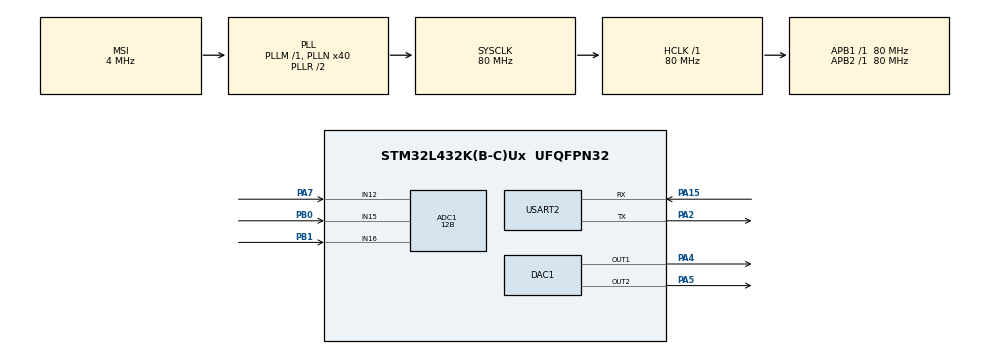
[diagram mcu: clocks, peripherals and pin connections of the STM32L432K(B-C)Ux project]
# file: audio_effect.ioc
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ADC1.Channel-0\#ChannelRegularConversion=ADC_CHANNEL_15
ADC1.Channel-3\#ChannelRegularConversion=ADC_CHANNEL_16
ADC1.Channel-4\#ChannelRegularConversion=ADC_CHANNEL_12
ADC1.ClockPrescaler=ADC_CLOCK_ASYNC_DIV1
ADC1.ContinuousConvMode=DISABLE
ADC1.DMAContinuousRequests=DISABLE
ADC1.DataAlign=ADC_DATAALIGN_RIGHT
ADC1.DiscontinuousConvMode=DISABLE
ADC1.EOCSelection=ADC_EOC_SINGLE_CONV
ADC1.EnableAnalogWatchDog1=false
ADC1.EnableAnalogWatchDog2=false
ADC1.EnableAnalogWatchDog3=false
ADC1.EnableInjectedConversion=DISABLE
ADC1.EnableRegularConversion=ENABLE
ADC1.ExternalTrigConv=ADC_SOFTWARE_START
ADC1.ExternalTrigConvEdge=ADC_EXTERNALTRIGCONVEDGE_NONE
ADC1.LowPowerAutoWait=DISABLE
ADC1.NbrOfConversion=3
ADC1.NbrOfConversionFlag=1
ADC1.OffsetNumber-0\#ChannelRegularConversion=ADC_OFFSET_NONE
ADC1.OffsetNumber-3\#ChannelRegularConversion=ADC_OFFSET_NONE
ADC1.OffsetNumber-4\#ChannelRegularConversion=ADC_OFFSET_NONE
ADC1.Overrun=ADC_OVR_DATA_PRESERVED
ADC1.OversamplingMode=DISABLE
ADC1.Rank-0\#ChannelRegularConversion=1
ADC1.Rank-3\#ChannelRegularConversion=2
ADC1.Rank-4\#ChannelRegularConversion=3
ADC1.Resolution=ADC_RESOLUTION_12B
ADC1.SamplingTime-0\#ChannelRegularConversion=ADC_SAMPLETIME_6CYCLES_5
ADC1.SamplingTime-3\#ChannelRegularConversion=ADC_SAMPLETIME_2CYCLES_5
ADC1.SamplingTime-4\#ChannelRegularConversion=ADC_SAMPLETIME_2CYCLES_5
ADC1.ScanConvMode=ADC_SCAN_ENABLE
ADC1.master=1
DAC1.DAC_Channel-DAC_OUT2=DAC_CHANNEL_2
DAC1.DAC_OutputBuffer-DAC_OUT1=DAC_OUTPUTBUFFER_DISABLE
DAC1.DAC_OutputBuffer-DAC_OUT2=DAC_OUTPUTBUFFER_DISABLE
DAC1.DAC_SampleAndHold-DAC_OUT1=DAC_SAMPLEANDHOLD_DISABLE
DAC1.DAC_Trigger-DAC_OUT1=DAC_TRIGGER_NONE
DAC1.DAC_Trigger-DAC_OUT2=DAC_TRIGGER_NONE
Mcu.Family=STM32L4
Mcu.Name=STM32L432K(B-C)Ux
Mcu.Package=UFQFPN32
NVIC.PriorityGroup=NVIC_PRIORITYGROUP_4
NVIC.TIM2_IRQn=true\:0\:0\:false\:false\:true
NVIC.TIM7_IRQn=true\:0\:0\:false\:false\:true
PA15\ (JTDI).Mode=Asynchronous
PA15\ (JTDI).Signal=USART2_RX
PA2.Mode=Asynchronous
PA2.Signal=USART2_TX
PA4.Signal=COMP_DAC11_group
PA5.Signal=COMP_DAC12_group
PA7.Signal=ADCx_IN12
PB0.Signal=ADCx_IN15
PB1.Signal=ADCx_IN16
ProjectManager.HeapSize=0x200
ProjectManager.StackSize=0x400
ProjectManager.TargetToolchain=EWARM
RCC.ADCCLockSelection=RCC_ADCCLKSOURCE_SYSCLK
RCC.ADCFreq_Value=80000000
RCC.AHBFreq_Value=80000000
RCC.APB1Freq_Value=80000000
RCC.APB1TimFreq_Value=80000000
RCC.APB2Freq_Value=80000000
RCC.APB2TimFreq_Value=80000000
RCC.CortexFreq_Value=80000000
RCC.HCLKFreq_Value=80000000
RCC.HSE_VALUE=8000000
RCC.HSI48_VALUE=48000000
RCC.HSI_VALUE=16000000
RCC.LSE_VALUE=32768
RCC.MSI_VALUE=4000000
RCC.PLLN=40
RCC.PLLSAI1N=16
RCC.SYSCLKFreq_VALUE=80000000
RCC.SYSCLKSource=RCC_SYSCLKSOURCE_PLLCLK
RCC.USBFreq_Value=32000000
RCC.VCOOutputFreq_Value=160000000
SH.ADCx_IN12.0=ADC1_IN12,IN12-Single-Ended
SH.ADCx_IN15.0=ADC1_IN15,IN15-Single-Ended
SH.ADCx_IN16.0=ADC1_IN16,IN16-Single-Ended
SH.COMP_DAC11_group.0=DAC1_OUT1,DAC_OUT1
SH.COMP_DAC12_group.0=DAC1_OUT2,DAC_OUT2
TIM2.Period=1666
TIM2.Prescaler=0
TIM2.TIM_MasterOutputTrigger=TIM_TRGO_ENABLE
TIM6.Period=1000
TIM6.Prescaler=48000
TIM6.TIM_MasterOutputTrigger=TIM_TRGO_UPDATE
TIM7.Period=999
TIM7.Prescaler=0
TIM7.TIM_MasterOutputTrigger=TIM_TRGO_ENABLE
USART2.VirtualMode-Asynchronous=VM_ASYNC
VP_TIM2_VS_ClockSourceINT.Mode=Internal
VP_TIM6_VS_ClockSourceINT.Mode=Enable_Timer
VP_TIM7_VS_ClockSourceINT.Mode=Enable_Timer
board=audio_effect

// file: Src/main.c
/**
  ******************************************************************************
  * File Name          : main.c
  * Description        : Main program body
  ******************************************************************************
  ** This notice applies to any and all portions of this file
  * that are not between comment pairs USER CODE BEGIN and
  * USER CODE END. Other portions of this file, whether
  * inserted by the user or by software development tools
  * are owned by their respective copyright owners.
  *
  * COPYRIGHT(c) 2017 STMicroelectronics
  *
  * Redistribution and use in source and binary forms, with or without modification,
  * are permitted provided that the following conditions are met:
  *   1. Redistributions of source code must retain the above copyright notice,
  *      this list of conditions and the following disclaimer.
  *   2. Redistributions in binary form must reproduce the above copyright notice,
  *      this list of conditions and the following disclaimer in the documentation
  *      and/or other materials provided with the distribution.
  *   3. Neither the name of STMicroelectronics nor the names of its contributors
  *      may be used to endorse or promote products derived from this software
  *      without specific prior written permission.
  *
  * THIS SOFTWARE IS PROVIDED BY THE COPYRIGHT HOLDERS AND CONTRIBUTORS "AS IS"
  * AND ANY EXPRESS OR IMPLIED WARRANTIES, INCLUDING, BUT NOT LIMITED TO, THE
  * IMPLIED WARRANTIES OF MERCHANTABILITY AND FITNESS FOR A PARTICULAR PURPOSE ARE
  * DISCLAIMED. IN NO EVENT SHALL THE COPYRIGHT HOLDER OR CONTRIBUTORS BE LIABLE
  * FOR ANY DIRECT, INDIRECT, INCIDENTAL, SPECIAL, EXEMPLARY, OR CONSEQUENTIAL
  * DAMAGES (INCLUDING, BUT NOT LIMITED TO, PROCUREMENT OF SUBSTITUTE GOODS OR
  * SERVICES; LOSS OF USE, DATA, OR PROFITS; OR BUSINESS INTERRUPTION) HOWEVER
  * CAUSED AND ON ANY THEORY OF LIABILITY, WHETHER IN CONTRACT, STRICT LIABILITY,
  * OR TORT (INCLUDING NEGLIGENCE OR OTHERWISE) ARISING IN ANY WAY OUT OF THE USE
  * OF THIS SOFTWARE, EVEN IF ADVISED OF THE POSSIBILITY OF SUCH DAMAGE.
  *
  ******************************************************************************
  */
#include "main.h"
#include "stm32l4xx_hal.h"

/* USER CODE BEGIN Includes */
#include "processing.h"
/* USER CODE END Includes */

ADC_HandleTypeDef hadc1;

DAC_HandleTypeDef hdac1;

TIM_HandleTypeDef htim2;
TIM_HandleTypeDef htim6;
TIM_HandleTypeDef htim7;

UART_HandleTypeDef huart2;

/* USER CODE BEGIN PV */
/* Private variables ---------------------------------------------------------*/
ADC_HandleTypeDef hadc1;
DAC_HandleTypeDef hdac1;
TIM_HandleTypeDef htim2;
TIM_HandleTypeDef htim6;
TIM_HandleTypeDef htim7;
UART_HandleTypeDef huart2;

int a;
/* USER CODE END PV */

void SystemClock_Config(void);
static void MX_GPIO_Init(void);
static void MX_ADC1_Init(void);
static void MX_DAC1_Init(void);
static void MX_USART2_UART_Init(void);
static void MX_TIM6_Init(void);
static void MX_TIM7_Init(void);
static void MX_TIM2_Init(void);

/* USER CODE BEGIN PFP */
/* Private function prototypes -----------------------------------------------*/

void HAL_TIM_PeriodElapsedCallback(TIM_HandleTypeDef *htim){
 if(htim->Instance == TIM7){                    // ~1Hz
    HandleTim_7_IRQ();
 }
 if(htim->Instance == TIM2){			// ~48kHz
    HandleTim_2_IRQ();
 }
}

/* USER CODE END PFP */

int main(void)
{

  /* MCU Configuration----------------------------------------------------------*/

  /* Reset of all peripherals, Initializes the Flash interface and the Systick. */
  HAL_Init();

  /* Configure the system clock */
  SystemClock_Config();

  /* Initialize all configured peripherals */
  MX_GPIO_Init();
  MX_ADC1_Init();
  MX_DAC1_Init();
  MX_USART2_UART_Init();
  MX_TIM6_Init();
  MX_TIM7_Init();
  MX_TIM2_Init();

  /* USER CODE BEGIN 2 */
  HAL_TIM_Base_Start_IT(&htim6);
  HAL_TIM_Base_Start_IT(&htim7);
  HAL_TIM_Base_Start_IT(&htim2);
  HAL_ADC_Start(&hadc1);
  HAL_DAC_Start(&hdac1, DAC_CHANNEL_1);

  /* USER CODE END 2 */

  /* Infinite loop */
  while (1)
  {

  }

}

/** System Clock Configuration
*/
void SystemClock_Config(void)
{

  RCC_OscInitTypeDef RCC_OscInitStruct;
  RCC_ClkInitTypeDef RCC_ClkInitStruct;
  RCC_PeriphCLKInitTypeDef PeriphClkInit;

    /**Initializes the CPU, AHB and APB busses clocks
    */
  RCC_OscInitStruct.OscillatorType = RCC_OSCILLATORTYPE_MSI;
  RCC_OscInitStruct.MSIState = RCC_MSI_ON;
  RCC_OscInitStruct.MSICalibrationValue = 0;
  RCC_OscInitStruct.MSIClockRange = RCC_MSIRANGE_6;
  RCC_OscInitStruct.PLL.PLLState = RCC_PLL_ON;
  RCC_OscInitStruct.PLL.PLLSource = RCC_PLLSOURCE_MSI;
  RCC_OscInitStruct.PLL.PLLM = 1;
  RCC_OscInitStruct.PLL.PLLN = 40;
  RCC_OscInitStruct.PLL.PLLP = RCC_PLLP_DIV7;
  RCC_OscInitStruct.PLL.PLLQ = RCC_PLLQ_DIV2;
  RCC_OscInitStruct.PLL.PLLR = RCC_PLLR_DIV2;
  if (HAL_RCC_OscConfig(&RCC_OscInitStruct) != HAL_OK)
  {
    _Error_Handler(__FILE__, __LINE__);
  }

    /**Initializes the CPU, AHB and APB busses clocks
    */
  RCC_ClkInitStruct.ClockType = RCC_CLOCKTYPE_HCLK|RCC_CLOCKTYPE_SYSCLK
                              |RCC_CLOCKTYPE_PCLK1|RCC_CLOCKTYPE_PCLK2;
  RCC_ClkInitStruct.SYSCLKSource = RCC_SYSCLKSOURCE_PLLCLK;
  RCC_ClkInitStruct.AHBCLKDivider = RCC_SYSCLK_DIV1;
  RCC_ClkInitStruct.APB1CLKDivider = RCC_HCLK_DIV1;
  RCC_ClkInitStruct.APB2CLKDivider = RCC_HCLK_DIV1;

  if (HAL_RCC_ClockConfig(&RCC_ClkInitStruct, FLASH_LATENCY_4) != HAL_OK)
  {
    _Error_Handler(__FILE__, __LINE__);
  }

  PeriphClkInit.PeriphClockSelection = RCC_PERIPHCLK_USART2|RCC_PERIPHCLK_ADC;
  PeriphClkInit.Usart2ClockSelection = RCC_USART2CLKSOURCE_PCLK1;
  PeriphClkInit.AdcClockSelection = RCC_ADCCLKSOURCE_SYSCLK;
  if (HAL_RCCEx_PeriphCLKConfig(&PeriphClkInit) != HAL_OK)
  {
    _Error_Handler(__FILE__, __LINE__);
  }

    /**Configure the main internal regulator output voltage
    */
  if (HAL_PWREx_ControlVoltageScaling(PWR_REGULATOR_VOLTAGE_SCALE1) != HAL_OK)
  {
    _Error_Handler(__FILE__, __LINE__);
  }

    /**Configure the Systick interrupt time
    */
  HAL_SYSTICK_Config(HAL_RCC_GetHCLKFreq()/1000);

    /**Configure the Systick
    */
  HAL_SYSTICK_CLKSourceConfig(SYSTICK_CLKSOURCE_HCLK);

  /* SysTick_IRQn interrupt configuration */
  HAL_NVIC_SetPriority(SysTick_IRQn, 0, 0);
}

/* ADC1 init function */
static void MX_ADC1_Init(void)
{

  ADC_ChannelConfTypeDef sConfig;

    /**Common config
    */
  hadc1.Instance = ADC1;
  hadc1.Init.ClockPrescaler = ADC_CLOCK_ASYNC_DIV1;
  hadc1.Init.Resolution = ADC_RESOLUTION_12B;
  hadc1.Init.DataAlign = ADC_DATAALIGN_RIGHT;
  hadc1.Init.ScanConvMode = ADC_SCAN_ENABLE;
  hadc1.Init.EOCSelection = ADC_EOC_SINGLE_CONV;
  hadc1.Init.LowPowerAutoWait = DISABLE;
  hadc1.Init.ContinuousConvMode = DISABLE;
  hadc1.Init.NbrOfConversion = 3;
  hadc1.Init.DiscontinuousConvMode = DISABLE;
  hadc1.Init.NbrOfDiscConversion = 1;
  hadc1.Init.ExternalTrigConv = ADC_SOFTWARE_START;
  hadc1.Init.ExternalTrigConvEdge = ADC_EXTERNALTRIGCONVEDGE_NONE;
  hadc1.Init.DMAContinuousRequests = DISABLE;
  hadc1.Init.Overrun = ADC_OVR_DATA_PRESERVED;
  hadc1.Init.OversamplingMode = DISABLE;
  if (HAL_ADC_Init(&hadc1) != HAL_OK)
  {
    _Error_Handler(__FILE__, __LINE__);
  }

    /**Configure Regular Channel
    */
  sConfig.Channel = ADC_CHANNEL_15;
  sConfig.Rank = 1;
  sConfig.SamplingTime = ADC_SAMPLETIME_6CYCLES_5;
  sConfig.SingleDiff = ADC_SINGLE_ENDED;
  sConfig.OffsetNumber = ADC_OFFSET_NONE;
  sConfig.Offset = 0;
  if (HAL_ADC_ConfigChannel(&hadc1, &sConfig) != HAL_OK)
  {
    _Error_Handler(__FILE__, __LINE__);
  }

    /**Configure Regular Channel
    */
  sConfig.Channel = ADC_CHANNEL_16;
  sConfig.Rank = 2;
  sConfig.SamplingTime = ADC_SAMPLETIME_2CYCLES_5;
  if (HAL_ADC_ConfigChannel(&hadc1, &sConfig) != HAL_OK)
  {
    _Error_Handler(__FILE__, __LINE__);
  }

    /**Configure Regular Channel
    */
  sConfig.Channel = ADC_CHANNEL_12;
  sConfig.Rank = 3;
  if (HAL_ADC_ConfigChannel(&hadc1, &sConfig) != HAL_OK)
  {
    _Error_Handler(__FILE__, __LINE__);
  }

}

/* DAC1 init function */
static void MX_DAC1_Init(void)
{

  DAC_ChannelConfTypeDef sConfig;

    /**DAC Initialization
    */
  hdac1.Instance = DAC1;
  if (HAL_DAC_Init(&hdac1) != HAL_OK)
  {
    _Error_Handler(__FILE__, __LINE__);
  }

    /**DAC channel OUT1 config
    */
  sConfig.DAC_SampleAndHold = DAC_SAMPLEANDHOLD_DISABLE;
  sConfig.DAC_Trigger = DAC_TRIGGER_NONE;
  sConfig.DAC_OutputBuffer = DAC_OUTPUTBUFFER_DISABLE;
  sConfig.DAC_ConnectOnChipPeripheral = DAC_CHIPCONNECT_DISABLE;
  sConfig.DAC_UserTrimming = DAC_TRIMMING_FACTORY;
  if (HAL_DAC_ConfigChannel(&hdac1, &sConfig, DAC_CHANNEL_1) != HAL_OK)
  {
    _Error_Handler(__FILE__, __LINE__);
  }

    /**DAC channel OUT2 config
    */
  sConfig.DAC_ConnectOnChipPeripheral = DAC_CHIPCONNECT_DISABLE;
  if (HAL_DAC_ConfigChannel(&hdac1, &sConfig, DAC_CHANNEL_2) != HAL_OK)
  {
    _Error_Handler(__FILE__, __LINE__);
  }

}

/* TIM2 init function */
static void MX_TIM2_Init(void)
{

  TIM_ClockConfigTypeDef sClockSourceConfig;
  TIM_MasterConfigTypeDef sMasterConfig;

  htim2.Instance = TIM2;
  htim2.Init.Prescaler = 0;
  htim2.Init.CounterMode = TIM_COUNTERMODE_UP;
  htim2.Init.Period = 1666;
  htim2.Init.ClockDivision = TIM_CLOCKDIVISION_DIV1;
  if (HAL_TIM_Base_Init(&htim2) != HAL_OK)
  {
    _Error_Handler(__FILE__, __LINE__);
  }

  sClockSourceConfig.ClockSource = TIM_CLOCKSOURCE_INTERNAL;
  if (HAL_TIM_ConfigClockSource(&htim2, &sClockSourceConfig) != HAL_OK)
  {
    _Error_Handler(__FILE__, __LINE__);
  }

  sMasterConfig.MasterOutputTrigger = TIM_TRGO_ENABLE;
  sMasterConfig.MasterSlaveMode = TIM_MASTERSLAVEMODE_DISABLE;
  if (HAL_TIMEx_MasterConfigSynchronization(&htim2, &sMasterConfig) != HAL_OK)
  {
    _Error_Handler(__FILE__, __LINE__);
  }

}

/* TIM6 init function */
static void MX_TIM6_Init(void)
{

  TIM_MasterConfigTypeDef sMasterConfig;

  htim6.Instance = TIM6;
  htim6.Init.Prescaler = 48000;
  htim6.Init.CounterMode = TIM_COUNTERMODE_UP;
  htim6.Init.Period = 1000;
  if (HAL_TIM_Base_Init(&htim6) != HAL_OK)
  {
    _Error_Handler(__FILE__, __LINE__);
  }

  sMasterConfig.MasterOutputTrigger = TIM_TRGO_UPDATE;
  sMasterConfig.MasterSlaveMode = TIM_MASTERSLAVEMODE_DISABLE;
  if (HAL_TIMEx_MasterConfigSynchronization(&htim6, &sMasterConfig) != HAL_OK)
  {
    _Error_Handler(__FILE__, __LINE__);
  }

}

/* TIM7 init function */
static void MX_TIM7_Init(void)
{

  TIM_MasterConfigTypeDef sMasterConfig;

  htim7.Instance = TIM7;
  htim7.Init.Prescaler = 9999;
  htim7.Init.CounterMode = TIM_COUNTERMODE_UP;
  htim7.Init.Period = 79999;
  if (HAL_TIM_Base_Init(&htim7) != HAL_OK)
  {
    _Error_Handler(__FILE__, __LINE__);
  }

  sMasterConfig.MasterOutputTrigger = TIM_TRGO_ENABLE;
  sMasterConfig.MasterSlaveMode = TIM_MASTERSLAVEMODE_DISABLE;
  if (HAL_TIMEx_MasterConfigSynchronization(&htim7, &sMasterConfig) != HAL_OK)
  {
    _Error_Handler(__FILE__, __LINE__);
  }

}

/* USART2 init function */
static void MX_USART2_UART_Init(void)
{

  huart2.Instance = USART2;
  huart2.Init.BaudRate = 115200;
  huart2.Init.WordLength = UART_WORDLENGTH_7B;
  huart2.Init.StopBits = UART_STOPBITS_1;
  huart2.Init.Parity = UART_PARITY_NONE;
  huart2.Init.Mode = UART_MODE_TX_RX;
  huart2.Init.HwFlowCtl = UART_HWCONTROL_NONE;
  huart2.Init.OverSampling = UART_OVERSAMPLING_16;
  huart2.Init.OneBitSampling = UART_ONE_BIT_SAMPLE_DISABLE;
  huart2.AdvancedInit.AdvFeatureInit = UART_ADVFEATURE_NO_INIT;
  if (HAL_UART_Init(&huart2) != HAL_OK)
  {
    _Error_Handler(__FILE__, __LINE__);
  }

}

/** Configure pins as
        * Analog
        * Input
        * Output
        * EVENT_OUT
        * EXTI
*/
static void MX_GPIO_Init(void)
{

  GPIO_InitTypeDef GPIO_InitStruct;

  /* GPIO Ports Clock Enable */
  __HAL_RCC_GPIOA_CLK_ENABLE();
  __HAL_RCC_GPIOB_CLK_ENABLE();

  /*Configure GPIO pin : PB4 */
  GPIO_InitStruct.Pin = GPIO_PIN_4;
  GPIO_InitStruct.Mode = GPIO_MODE_INPUT;
  GPIO_InitStruct.Pull = GPIO_NOPULL;
  HAL_GPIO_Init(GPIOB, &GPIO_InitStruct);

}

void _Error_Handler(char * file, int line)
{
  while(1)
  {
  }
}

/************************ (C) COPYRIGHT STMicroelectronics *****END OF FILE****/
